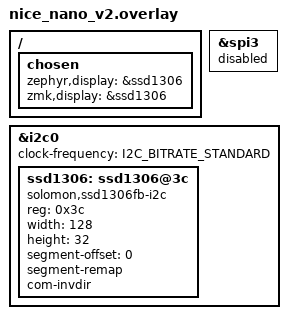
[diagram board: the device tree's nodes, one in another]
/*
 * nice_nano_v2 overlay — OLED enabled, RGB disabled
 * OLED: SSD1306 128x32 over I²C @ 0x3C
 * Works with SuperMini nRF52840 (build as -b nice_nano_v2)
 */

/* Make sure WS2812 underglow (SPI3) stays off */
&spi3 {
    status = "disabled";
};

&i2c0 {
    status = "okay";
    clock-frequency = <I2C_BITRATE_STANDARD>;  /* 100 kHz */

    /* 0.91" SSD1306 module (commonly 128x32 at address 0x3C) */
    ssd1306: ssd1306@3c {
        compatible = "solomon,ssd1306fb-i2c";
        reg = <0x3c>;      /* change to <0x3d> if your board is jumpered to 0x3D */
        width = <128>;
        height = <32>;     /* use <64> if your panel is 128x64 */

        /* Required by Zephyr 3.5 binding */
        segment-offset = <0>;

        /* Typical orientation flags for these modules */
        segment-remap;
        com-invdir;

        /* Optional tuning (usually fine at defaults)
         * display-offset = <0>;
         * page-offset = <0>;
         * prechargep = <0x22>;
         */
    };
};

 / {
    chosen {
        /* Ensure no underglow is selected anywhere */
        /delete-property/ zmk,underglow;

        /* Use the SSD1306 as the system/ZMK status display */
        zephyr,display = &ssd1306;
        zmk,display    = &ssd1306;
    };
};
